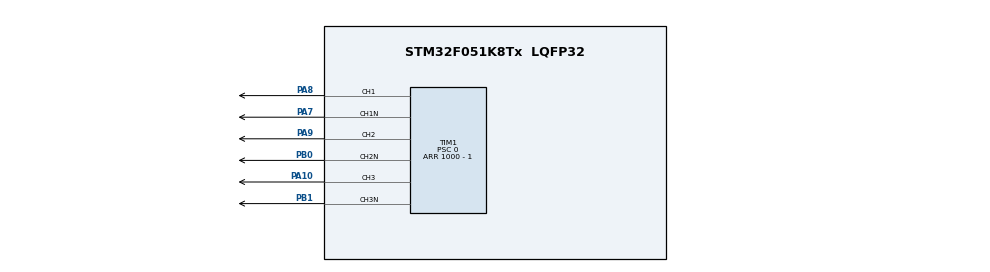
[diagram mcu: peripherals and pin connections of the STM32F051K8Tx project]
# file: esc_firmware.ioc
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Mcu.Family=STM32F0
Mcu.Name=STM32F051K8Tx
Mcu.Package=LQFP32
NVIC.TIM14_IRQn=true\:0\:0\:false\:false\:true\:true\:true\:true
PA10.Signal=S_TIM1_CH3
PA13.Mode=Serial_Wire
PA13.Signal=SYS_SWDIO
PA14.Mode=Serial_Wire
PA14.Signal=SYS_SWCLK
PA7.Mode=PWM Generation1 CH1 CH1N
PA7.Signal=TIM1_CH1N
PA8.Signal=S_TIM1_CH1
PA9.Signal=S_TIM1_CH2
PB0.Mode=PWM Generation2 CH2 CH2N
PB0.Signal=TIM1_CH2N
PB1.Mode=PWM Generation3 CH3 CH3N
PB1.Signal=TIM1_CH3N
ProjectManager.HeapSize=0x200
ProjectManager.StackSize=0x400
ProjectManager.TargetToolchain=CMake
RCC.AHBFreq_Value=48000000
RCC.APB1Freq_Value=48000000
RCC.APB1TimFreq_Value=48000000
RCC.HCLKFreq_Value=48000000
RCC.PLLMUL=RCC_PLL_MUL12
RCC.SYSCLKFreq_VALUE=48000000
RCC.SYSCLKSource=RCC_SYSCLKSOURCE_PLLCLK
SH.S_TIM1_CH1.0=TIM1_CH1,PWM Generation1 CH1 CH1N
SH.S_TIM1_CH2.0=TIM1_CH2,PWM Generation2 CH2 CH2N
SH.S_TIM1_CH3.0=TIM1_CH3,PWM Generation3 CH3 CH3N
TIM1.AutoReloadPreload=TIM_AUTORELOAD_PRELOAD_ENABLE
TIM1.AutomaticOutput=TIM_AUTOMATICOUTPUT_ENABLE
TIM1.Channel-Output\ Compare3\ CH3\ CH3N=TIM_CHANNEL_3
TIM1.Channel-PWM\ Generation1\ CH1\ CH1N=TIM_CHANNEL_1
TIM1.Channel-PWM\ Generation2\ CH2\ CH2N=TIM_CHANNEL_2
TIM1.Channel-PWM\ Generation3\ CH3\ CH3N=TIM_CHANNEL_3
TIM1.CounterMode=TIM_COUNTERMODE_CENTERALIGNED1
TIM1.DeadTime=48
TIM1.OCNPolarity_1=TIM_OCNPOLARITY_HIGH
TIM1.OCNPolarity_2=TIM_OCNPOLARITY_HIGH
TIM1.Period=1000 - 1
TIM1.Prescaler=0
TIM14.Period=20000 - 1
TIM14.Prescaler=47
VP_TIM14_VS_ClockSourceINT.Mode=Enable_Timer
VP_TIM1_VS_ClockSourceINT.Mode=Internal
board=custom

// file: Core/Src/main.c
/* USER CODE BEGIN Header */
/**
  ******************************************************************************
  * @file           : main.c
  * @brief          : Main program body
  ******************************************************************************
  * @attention
  *
  * Copyright (c) 2026 STMicroelectronics.
  * All rights reserved.
  *
  * This software is licensed under terms that can be found in the LICENSE file
  * in the root directory of this software component.
  * If no LICENSE file comes with this software, it is provided AS-IS.
  *
  ******************************************************************************
  */
/* USER CODE END Header */
#include "main.h"
#include "tim.h"
#include "gpio.h"

/* USER CODE BEGIN Includes */
#include "pwm_generator.h"
#include "phase.h"
/* USER CODE END Includes */

void SystemClock_Config(void);

int main(void)
{

  /* MCU Configuration--------------------------------------------------------*/

  /* Reset of all peripherals, Initializes the Flash interface and the Systick. */
  LL_APB1_GRP2_EnableClock(LL_APB1_GRP2_PERIPH_SYSCFG);
  LL_APB1_GRP1_EnableClock(LL_APB1_GRP1_PERIPH_PWR);

  /* SysTick_IRQn interrupt configuration */
  NVIC_SetPriority(SysTick_IRQn, 3);

  /* Configure the system clock */
  SystemClock_Config();

  /* Initialize all configured peripherals */
  MX_GPIO_Init();
  MX_TIM1_Init();
  MX_TIM14_Init();

  /* Infinite loop */
  /* USER CODE BEGIN WHILE */
  pwm_set(100);
  pwm_start();
  motor_sync();
  timer_interrupt_start();
  while (1)
  {
    /* USER CODE END WHILE */

  }
}

void SystemClock_Config(void)
{
  LL_FLASH_SetLatency(LL_FLASH_LATENCY_1);
  while(LL_FLASH_GetLatency() != LL_FLASH_LATENCY_1)
  {
  }
  LL_RCC_HSI_Enable();

   /* Wait till HSI is ready */
  while(LL_RCC_HSI_IsReady() != 1)
  {

  }
  LL_RCC_HSI_SetCalibTrimming(16);
  LL_RCC_PLL_ConfigDomain_SYS(LL_RCC_PLLSOURCE_HSI_DIV_2, LL_RCC_PLL_MUL_12);
  LL_RCC_PLL_Enable();

   /* Wait till PLL is ready */
  while(LL_RCC_PLL_IsReady() != 1)
  {

  }
  LL_RCC_SetAHBPrescaler(LL_RCC_SYSCLK_DIV_1);
  LL_RCC_SetAPB1Prescaler(LL_RCC_APB1_DIV_1);
  LL_RCC_SetSysClkSource(LL_RCC_SYS_CLKSOURCE_PLL);

   /* Wait till System clock is ready */
  while(LL_RCC_GetSysClkSource() != LL_RCC_SYS_CLKSOURCE_STATUS_PLL)
  {

  }
  LL_Init1msTick(48000000);
  LL_SetSystemCoreClock(48000000);
}

void Error_Handler(void)
{
  __disable_irq();
  while (1)
  {
  }
}
